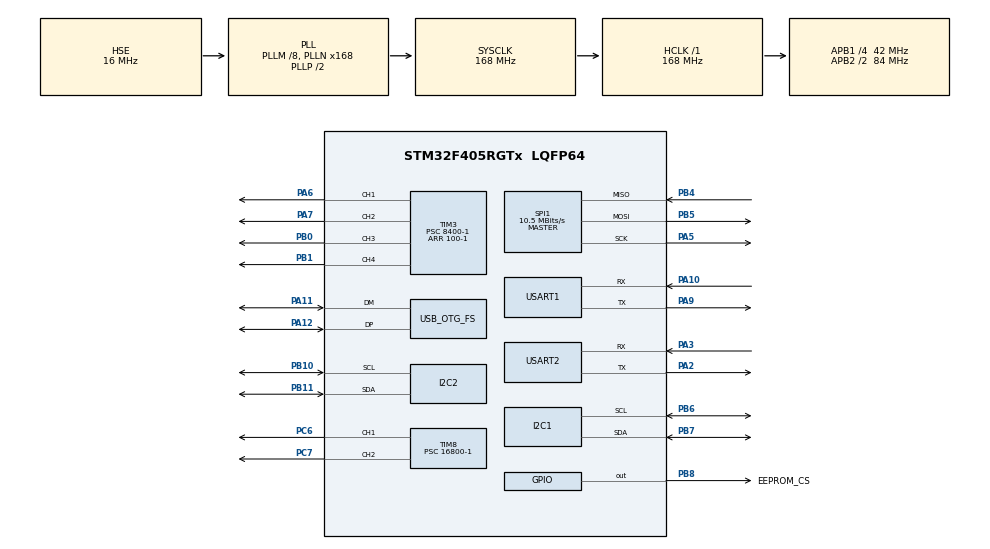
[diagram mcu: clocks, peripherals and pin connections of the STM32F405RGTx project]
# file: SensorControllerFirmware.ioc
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I2C1.I2C_Mode=I2C_Fast
Mcu.Family=STM32F4
Mcu.Name=STM32F405RGTx
Mcu.Package=LQFP64
NVIC.OTG_FS_IRQn=true\:0\:0\:false\:false\:true\:false\:true\:true
NVIC.PriorityGroup=NVIC_PRIORITYGROUP_4
PA10.Mode=Asynchronous
PA10.Signal=USART1_RX
PA11.Mode=Device_Only
PA11.Signal=USB_OTG_FS_DM
PA12.Mode=Device_Only
PA12.Signal=USB_OTG_FS_DP
PA13.Mode=Trace_Asynchronous_SW
PA13.Signal=SYS_JTMS-SWDIO
PA14.Mode=Trace_Asynchronous_SW
PA14.Signal=SYS_JTCK-SWCLK
PA2.Mode=Asynchronous
PA2.Signal=USART2_TX
PA3.Mode=Asynchronous
PA3.Signal=USART2_RX
PA5.Mode=Full_Duplex_Master
PA5.Signal=SPI1_SCK
PA6.Signal=S_TIM3_CH1
PA7.Signal=S_TIM3_CH2
PA9.Mode=Asynchronous
PA9.Signal=USART1_TX
PB0.Signal=S_TIM3_CH3
PB1.Signal=S_TIM3_CH4
PB10.Mode=I2C
PB10.Signal=I2C2_SCL
PB11.Mode=I2C
PB11.Signal=I2C2_SDA
PB3.Mode=Trace_Asynchronous_SW
PB3.Signal=SYS_JTDO-SWO
PB4.Mode=Full_Duplex_Master
PB4.Signal=SPI1_MISO
PB5.Mode=Full_Duplex_Master
PB5.Signal=SPI1_MOSI
PB6.Mode=I2C
PB6.Signal=I2C1_SCL
PB7.Mode=I2C
PB7.Signal=I2C1_SDA
PB8.GPIO_Label=EEPROM_CS
PB8.PinState=GPIO_PIN_SET
PB8.Signal=GPIO_Output
PC6.Signal=S_TIM8_CH1
PC7.Signal=S_TIM8_CH2
PH0-OSC_IN.Mode=HSE-External-Oscillator
PH0-OSC_IN.Signal=RCC_OSC_IN
PH1-OSC_OUT.Mode=HSE-External-Oscillator
PH1-OSC_OUT.Signal=RCC_OSC_OUT
ProjectManager.HeapSize=0x200
ProjectManager.StackSize=0x400
ProjectManager.TargetToolchain=STM32CubeIDE
RCC.48MHZClocksFreq_Value=48000000
RCC.AHBFreq_Value=168000000
RCC.APB1CLKDivider=RCC_HCLK_DIV4
RCC.APB1Freq_Value=42000000
RCC.APB1TimFreq_Value=84000000
RCC.APB2CLKDivider=RCC_HCLK_DIV2
RCC.APB2Freq_Value=84000000
RCC.APB2TimFreq_Value=168000000
RCC.CortexFreq_Value=168000000
RCC.HCLKFreq_Value=168000000
RCC.HSE_VALUE=16000000
RCC.HSI_VALUE=16000000
RCC.LSE_VALUE=32768
RCC.PLLM=8
RCC.PLLN=168
RCC.PLLQ=7
RCC.SYSCLKFreq_VALUE=168000000
RCC.SYSCLKSource=RCC_SYSCLKSOURCE_PLLCLK
RCC.VCOOutputFreq_Value=336000000
SH.S_TIM3_CH1.0=TIM3_CH1,PWM Generation1 CH1
SH.S_TIM3_CH2.0=TIM3_CH2,PWM Generation2 CH2
SH.S_TIM3_CH3.0=TIM3_CH3,PWM Generation3 CH3
SH.S_TIM3_CH4.0=TIM3_CH4,PWM Generation4 CH4
SH.S_TIM8_CH1.0=TIM8_CH1,PWM Generation1 CH1
SH.S_TIM8_CH2.0=TIM8_CH2,PWM Generation2 CH2
SPI1.BaudRatePrescaler=SPI_BAUDRATEPRESCALER_8
SPI1.CalculateBaudRate=10.5 MBits/s
SPI1.Direction=SPI_DIRECTION_2LINES
SPI1.Mode=SPI_MODE_MASTER
SPI1.VirtualType=VM_MASTER
TIM3.Channel-PWM\ Generation1\ CH1=TIM_CHANNEL_1
TIM3.Channel-PWM\ Generation2\ CH2=TIM_CHANNEL_2
TIM3.Channel-PWM\ Generation3\ CH3=TIM_CHANNEL_3
TIM3.Channel-PWM\ Generation4\ CH4=TIM_CHANNEL_4
TIM3.Period=100-1
TIM3.Prescaler=8400-1
TIM8.Channel-PWM\ Generation1\ CH1=TIM_CHANNEL_1
TIM8.Channel-PWM\ Generation2\ CH2=TIM_CHANNEL_2
TIM8.Period=100-1
TIM8.Prescaler=16800-1
USART1.VirtualMode=VM_ASYNC
USART2.VirtualMode=VM_ASYNC
USB_DEVICE.CLASS_NAME_FS=CDC
USB_DEVICE.VirtualMode-CDC_FS=Cdc
USB_DEVICE.VirtualModeFS=Cdc_FS
USB_OTG_FS.VirtualMode=Device_Only
VP_TIM3_VS_ClockSourceINT.Mode=Internal
VP_TIM8_VS_ClockSourceINT.Mode=Internal
VP_USB_DEVICE_VS_USB_DEVICE_CDC_FS.Mode=CDC_FS
board=custom

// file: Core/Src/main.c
/* USER CODE BEGIN Header */
/**
  ******************************************************************************
  * @file           : main.c
  * @brief          : Main program body
  ******************************************************************************
  * @attention
  *
  * Copyright (c) 2022 STMicroelectronics.
  * All rights reserved.
  *
  * This software is licensed under terms that can be found in the LICENSE file
  * in the root directory of this software component.
  * If no LICENSE file comes with this software, it is provided AS-IS.
  *
  ******************************************************************************
  */
/* USER CODE END Header */
#include "main.h"
#include "usb_device.h"

/* USER CODE BEGIN Includes */
#include "usbd_cdc_if.h"
#include <math.h>
#include "EEPROM.h"
#include "constants.h"
#include "I2Cdev.h"
#include "MPU6050.h"
/* USER CODE END Includes */

I2C_HandleTypeDef hi2c1;
I2C_HandleTypeDef hi2c2;

SPI_HandleTypeDef hspi1;

TIM_HandleTypeDef htim3;
TIM_HandleTypeDef htim8;

UART_HandleTypeDef huart1;
UART_HandleTypeDef huart2;

/* USER CODE BEGIN PV */
EEPROM eeprom;
/* USER CODE END PV */

void SystemClock_Config(void);
static void MX_GPIO_Init(void);
static void MX_I2C1_Init(void);
static void MX_USART2_UART_Init(void);
static void MX_I2C2_Init(void);
static void MX_USART1_UART_Init(void);
static void MX_TIM3_Init(void);
static void MX_TIM8_Init(void);
static void MX_SPI1_Init(void);

int main(void)
{

  /* MCU Configuration--------------------------------------------------------*/

  /* Reset of all peripherals, Initializes the Flash interface and the Systick. */
  HAL_Init();

  /* Configure the system clock */
  SystemClock_Config();

  /* Initialize all configured peripherals */
  MX_GPIO_Init();
  MX_I2C1_Init();
  MX_USART2_UART_Init();
  MX_USB_DEVICE_Init();
  MX_I2C2_Init();
  MX_USART1_UART_Init();
  MX_TIM3_Init();
  MX_TIM8_Init();
  MX_SPI1_Init();

  /* Infinite loop */
  /* USER CODE BEGIN WHILE */
  I2Cdev_init(&hi2c1);
  MPU6050_initialize();
  //EEPROM_ReadId(&eeprom, &j_id);
  /*
  HAL_GPIO_WritePin(CS_PORT, CS_PIN, GPIO_PIN_RESET);
  uint8_t id_reg = 0x90;
  uint8_t ret;
  uint32_t Temp = 0, Temp0 = 0, Temp1 = 0, Temp2 = 0;
  HAL_SPI_TransmitReceive(&hspi1, &id_reg, &ret, 1, 100);
  uint32_t dummy_data = 0xA5;
  HAL_SPI_TransmitReceive(&hspi1, &dummy_data, &Temp0, 1, 100);
  HAL_SPI_TransmitReceive(&hspi1, &dummy_data, &Temp1, 1, 100);
  HAL_SPI_TransmitReceive(&hspi1, &dummy_data, &Temp2, 1, 100);
  HAL_GPIO_WritePin(CS_PORT, CS_PIN, GPIO_PIN_SET);

  Temp = (Temp0 << 16) | (Temp1 << 8) | Temp2;
  */
  uint8_t logBuf[32];
  uint8_t bufLen;

  uint8_t devStatus = 0;
  devStatus = MPU6050_testConnection();
  while (1)
  {
    /* USER CODE END WHILE */

  }
}

void SystemClock_Config(void)
{
  RCC_OscInitTypeDef RCC_OscInitStruct = {0};
  RCC_ClkInitTypeDef RCC_ClkInitStruct = {0};

  /** Configure the main internal regulator output voltage
  */
  __HAL_RCC_PWR_CLK_ENABLE();
  __HAL_PWR_VOLTAGESCALING_CONFIG(PWR_REGULATOR_VOLTAGE_SCALE1);

  /** Initializes the RCC Oscillators according to the specified parameters
  * in the RCC_OscInitTypeDef structure.
  */
  RCC_OscInitStruct.OscillatorType = RCC_OSCILLATORTYPE_HSE;
  RCC_OscInitStruct.HSEState = RCC_HSE_ON;
  RCC_OscInitStruct.PLL.PLLState = RCC_PLL_ON;
  RCC_OscInitStruct.PLL.PLLSource = RCC_PLLSOURCE_HSE;
  RCC_OscInitStruct.PLL.PLLM = 8;
  RCC_OscInitStruct.PLL.PLLN = 168;
  RCC_OscInitStruct.PLL.PLLP = RCC_PLLP_DIV2;
  RCC_OscInitStruct.PLL.PLLQ = 7;
  if (HAL_RCC_OscConfig(&RCC_OscInitStruct) != HAL_OK)
  {
    Error_Handler();
  }

  /** Initializes the CPU, AHB and APB buses clocks
  */
  RCC_ClkInitStruct.ClockType = RCC_CLOCKTYPE_HCLK|RCC_CLOCKTYPE_SYSCLK
                              |RCC_CLOCKTYPE_PCLK1|RCC_CLOCKTYPE_PCLK2;
  RCC_ClkInitStruct.SYSCLKSource = RCC_SYSCLKSOURCE_PLLCLK;
  RCC_ClkInitStruct.AHBCLKDivider = RCC_SYSCLK_DIV1;
  RCC_ClkInitStruct.APB1CLKDivider = RCC_HCLK_DIV4;
  RCC_ClkInitStruct.APB2CLKDivider = RCC_HCLK_DIV2;

  if (HAL_RCC_ClockConfig(&RCC_ClkInitStruct, FLASH_LATENCY_5) != HAL_OK)
  {
    Error_Handler();
  }
}

static void MX_I2C1_Init(void)
{

  hi2c1.Instance = I2C1;
  hi2c1.Init.ClockSpeed = 400000;
  hi2c1.Init.DutyCycle = I2C_DUTYCYCLE_2;
  hi2c1.Init.OwnAddress1 = 0;
  hi2c1.Init.AddressingMode = I2C_ADDRESSINGMODE_7BIT;
  hi2c1.Init.DualAddressMode = I2C_DUALADDRESS_DISABLE;
  hi2c1.Init.OwnAddress2 = 0;
  hi2c1.Init.GeneralCallMode = I2C_GENERALCALL_DISABLE;
  hi2c1.Init.NoStretchMode = I2C_NOSTRETCH_DISABLE;
  if (HAL_I2C_Init(&hi2c1) != HAL_OK)
  {
    Error_Handler();
  }

}

static void MX_I2C2_Init(void)
{

  hi2c2.Instance = I2C2;
  hi2c2.Init.ClockSpeed = 100000;
  hi2c2.Init.DutyCycle = I2C_DUTYCYCLE_2;
  hi2c2.Init.OwnAddress1 = 0;
  hi2c2.Init.AddressingMode = I2C_ADDRESSINGMODE_7BIT;
  hi2c2.Init.DualAddressMode = I2C_DUALADDRESS_DISABLE;
  hi2c2.Init.OwnAddress2 = 0;
  hi2c2.Init.GeneralCallMode = I2C_GENERALCALL_DISABLE;
  hi2c2.Init.NoStretchMode = I2C_NOSTRETCH_DISABLE;
  if (HAL_I2C_Init(&hi2c2) != HAL_OK)
  {
    Error_Handler();
  }

}

static void MX_SPI1_Init(void)
{

  /* SPI1 parameter configuration*/
  hspi1.Instance = SPI1;
  hspi1.Init.Mode = SPI_MODE_MASTER;
  hspi1.Init.Direction = SPI_DIRECTION_2LINES;
  hspi1.Init.DataSize = SPI_DATASIZE_8BIT;
  hspi1.Init.CLKPolarity = SPI_POLARITY_LOW;
  hspi1.Init.CLKPhase = SPI_PHASE_1EDGE;
  hspi1.Init.NSS = SPI_NSS_SOFT;
  hspi1.Init.BaudRatePrescaler = SPI_BAUDRATEPRESCALER_8;
  hspi1.Init.FirstBit = SPI_FIRSTBIT_MSB;
  hspi1.Init.TIMode = SPI_TIMODE_DISABLE;
  hspi1.Init.CRCCalculation = SPI_CRCCALCULATION_DISABLE;
  hspi1.Init.CRCPolynomial = 10;
  if (HAL_SPI_Init(&hspi1) != HAL_OK)
  {
    Error_Handler();
  }

}

static void MX_TIM3_Init(void)
{

  TIM_ClockConfigTypeDef sClockSourceConfig = {0};
  TIM_MasterConfigTypeDef sMasterConfig = {0};
  TIM_OC_InitTypeDef sConfigOC = {0};

  htim3.Instance = TIM3;
  htim3.Init.Prescaler = 8400-1;
  htim3.Init.CounterMode = TIM_COUNTERMODE_UP;
  htim3.Init.Period = 100-1;
  htim3.Init.ClockDivision = TIM_CLOCKDIVISION_DIV1;
  htim3.Init.AutoReloadPreload = TIM_AUTORELOAD_PRELOAD_DISABLE;
  if (HAL_TIM_Base_Init(&htim3) != HAL_OK)
  {
    Error_Handler();
  }
  sClockSourceConfig.ClockSource = TIM_CLOCKSOURCE_INTERNAL;
  if (HAL_TIM_ConfigClockSource(&htim3, &sClockSourceConfig) != HAL_OK)
  {
    Error_Handler();
  }
  if (HAL_TIM_PWM_Init(&htim3) != HAL_OK)
  {
    Error_Handler();
  }
  sMasterConfig.MasterOutputTrigger = TIM_TRGO_RESET;
  sMasterConfig.MasterSlaveMode = TIM_MASTERSLAVEMODE_DISABLE;
  if (HAL_TIMEx_MasterConfigSynchronization(&htim3, &sMasterConfig) != HAL_OK)
  {
    Error_Handler();
  }
  sConfigOC.OCMode = TIM_OCMODE_PWM1;
  sConfigOC.Pulse = 0;
  sConfigOC.OCPolarity = TIM_OCPOLARITY_HIGH;
  sConfigOC.OCFastMode = TIM_OCFAST_DISABLE;
  if (HAL_TIM_PWM_ConfigChannel(&htim3, &sConfigOC, TIM_CHANNEL_1) != HAL_OK)
  {
    Error_Handler();
  }
  if (HAL_TIM_PWM_ConfigChannel(&htim3, &sConfigOC, TIM_CHANNEL_2) != HAL_OK)
  {
    Error_Handler();
  }
  if (HAL_TIM_PWM_ConfigChannel(&htim3, &sConfigOC, TIM_CHANNEL_3) != HAL_OK)
  {
    Error_Handler();
  }
  if (HAL_TIM_PWM_ConfigChannel(&htim3, &sConfigOC, TIM_CHANNEL_4) != HAL_OK)
  {
    Error_Handler();
  }
  HAL_TIM_MspPostInit(&htim3);

}

static void MX_TIM8_Init(void)
{

  TIM_ClockConfigTypeDef sClockSourceConfig = {0};
  TIM_MasterConfigTypeDef sMasterConfig = {0};
  TIM_OC_InitTypeDef sConfigOC = {0};
  TIM_BreakDeadTimeConfigTypeDef sBreakDeadTimeConfig = {0};

  htim8.Instance = TIM8;
  htim8.Init.Prescaler = 16800-1;
  htim8.Init.CounterMode = TIM_COUNTERMODE_UP;
  htim8.Init.Period = 100-1;
  htim8.Init.ClockDivision = TIM_CLOCKDIVISION_DIV1;
  htim8.Init.RepetitionCounter = 0;
  htim8.Init.AutoReloadPreload = TIM_AUTORELOAD_PRELOAD_DISABLE;
  if (HAL_TIM_Base_Init(&htim8) != HAL_OK)
  {
    Error_Handler();
  }
  sClockSourceConfig.ClockSource = TIM_CLOCKSOURCE_INTERNAL;
  if (HAL_TIM_ConfigClockSource(&htim8, &sClockSourceConfig) != HAL_OK)
  {
    Error_Handler();
  }
  if (HAL_TIM_PWM_Init(&htim8) != HAL_OK)
  {
    Error_Handler();
  }
  sMasterConfig.MasterOutputTrigger = TIM_TRGO_RESET;
  sMasterConfig.MasterSlaveMode = TIM_MASTERSLAVEMODE_DISABLE;
  if (HAL_TIMEx_MasterConfigSynchronization(&htim8, &sMasterConfig) != HAL_OK)
  {
    Error_Handler();
  }
  sConfigOC.OCMode = TIM_OCMODE_PWM1;
  sConfigOC.Pulse = 0;
  sConfigOC.OCPolarity = TIM_OCPOLARITY_HIGH;
  sConfigOC.OCNPolarity = TIM_OCNPOLARITY_HIGH;
  sConfigOC.OCFastMode = TIM_OCFAST_DISABLE;
  sConfigOC.OCIdleState = TIM_OCIDLESTATE_RESET;
  sConfigOC.OCNIdleState = TIM_OCNIDLESTATE_RESET;
  if (HAL_TIM_PWM_ConfigChannel(&htim8, &sConfigOC, TIM_CHANNEL_1) != HAL_OK)
  {
    Error_Handler();
  }
  if (HAL_TIM_PWM_ConfigChannel(&htim8, &sConfigOC, TIM_CHANNEL_2) != HAL_OK)
  {
    Error_Handler();
  }
  sBreakDeadTimeConfig.OffStateRunMode = TIM_OSSR_DISABLE;
  sBreakDeadTimeConfig.OffStateIDLEMode = TIM_OSSI_DISABLE;
  sBreakDeadTimeConfig.LockLevel = TIM_LOCKLEVEL_OFF;
  sBreakDeadTimeConfig.DeadTime = 0;
  sBreakDeadTimeConfig.BreakState = TIM_BREAK_DISABLE;
  sBreakDeadTimeConfig.BreakPolarity = TIM_BREAKPOLARITY_HIGH;
  sBreakDeadTimeConfig.AutomaticOutput = TIM_AUTOMATICOUTPUT_DISABLE;
  if (HAL_TIMEx_ConfigBreakDeadTime(&htim8, &sBreakDeadTimeConfig) != HAL_OK)
  {
    Error_Handler();
  }
  HAL_TIM_MspPostInit(&htim8);

}

static void MX_USART1_UART_Init(void)
{

  huart1.Instance = USART1;
  huart1.Init.BaudRate = 115200;
  huart1.Init.WordLength = UART_WORDLENGTH_8B;
  huart1.Init.StopBits = UART_STOPBITS_1;
  huart1.Init.Parity = UART_PARITY_NONE;
  huart1.Init.Mode = UART_MODE_TX_RX;
  huart1.Init.HwFlowCtl = UART_HWCONTROL_NONE;
  huart1.Init.OverSampling = UART_OVERSAMPLING_16;
  if (HAL_UART_Init(&huart1) != HAL_OK)
  {
    Error_Handler();
  }

}

static void MX_USART2_UART_Init(void)
{

  huart2.Instance = USART2;
  huart2.Init.BaudRate = 115200;
  huart2.Init.WordLength = UART_WORDLENGTH_8B;
  huart2.Init.StopBits = UART_STOPBITS_1;
  huart2.Init.Parity = UART_PARITY_NONE;
  huart2.Init.Mode = UART_MODE_TX_RX;
  huart2.Init.HwFlowCtl = UART_HWCONTROL_NONE;
  huart2.Init.OverSampling = UART_OVERSAMPLING_16;
  if (HAL_UART_Init(&huart2) != HAL_OK)
  {
    Error_Handler();
  }

}

static void MX_GPIO_Init(void)
{
  GPIO_InitTypeDef GPIO_InitStruct = {0};

  /* GPIO Ports Clock Enable */
  __HAL_RCC_GPIOH_CLK_ENABLE();
  __HAL_RCC_GPIOA_CLK_ENABLE();
  __HAL_RCC_GPIOB_CLK_ENABLE();
  __HAL_RCC_GPIOC_CLK_ENABLE();

  /*Configure GPIO pin Output Level */
  HAL_GPIO_WritePin(EEPROM_CS_GPIO_Port, EEPROM_CS_Pin, GPIO_PIN_SET);

  /*Configure GPIO pin : EEPROM_CS_Pin */
  GPIO_InitStruct.Pin = EEPROM_CS_Pin;
  GPIO_InitStruct.Mode = GPIO_MODE_OUTPUT_PP;
  GPIO_InitStruct.Pull = GPIO_NOPULL;
  GPIO_InitStruct.Speed = GPIO_SPEED_FREQ_LOW;
  HAL_GPIO_Init(EEPROM_CS_GPIO_Port, &GPIO_InitStruct);

}

void Error_Handler(void)
{
  __disable_irq();
  while (1)
  {
  }
}
